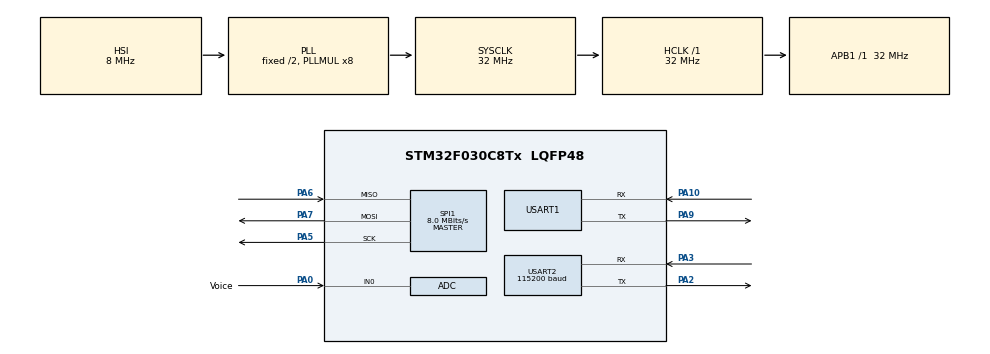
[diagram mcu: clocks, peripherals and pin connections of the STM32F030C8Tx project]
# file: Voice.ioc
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ADC.ClockPrescaler=ADC_CLOCK_ASYNC_DIV1
ADC.ContinuousConvMode=DISABLE
ADC.DMAContinuousRequests=ENABLE
ADC.DiscontinuousConvMode=DISABLE
ADC.ExternalTrigConv=ADC_SOFTWARE_START
ADC.Overrun=ADC_OVR_DATA_OVERWRITTEN
ADC.SamplingTime=ADC_SAMPLETIME_7CYCLES_5
Dma.ADC.1.Direction=DMA_PERIPH_TO_MEMORY
Dma.ADC.1.Instance=DMA1_Channel1
Dma.ADC.1.MemDataAlignment=DMA_MDATAALIGN_WORD
Dma.ADC.1.MemInc=DMA_MINC_ENABLE
Dma.ADC.1.Mode=DMA_CIRCULAR
Dma.ADC.1.PeriphDataAlignment=DMA_PDATAALIGN_WORD
Dma.ADC.1.PeriphInc=DMA_PINC_DISABLE
Dma.ADC.1.Priority=DMA_PRIORITY_LOW
Dma.Request0=SPI1_TX
Dma.Request1=ADC
Dma.SPI1_TX.0.Direction=DMA_MEMORY_TO_PERIPH
Dma.SPI1_TX.0.Instance=DMA1_Channel3
Dma.SPI1_TX.0.MemDataAlignment=DMA_MDATAALIGN_BYTE
Dma.SPI1_TX.0.MemInc=DMA_MINC_ENABLE
Dma.SPI1_TX.0.Mode=DMA_NORMAL
Dma.SPI1_TX.0.PeriphDataAlignment=DMA_PDATAALIGN_BYTE
Dma.SPI1_TX.0.PeriphInc=DMA_PINC_DISABLE
Dma.SPI1_TX.0.Priority=DMA_PRIORITY_LOW
Mcu.Family=STM32F0
Mcu.Name=STM32F030C8Tx
Mcu.Package=LQFP48
NVIC.DMA1_Channel1_IRQn=true\:0\:0\:false\:false\:true\:false\:true
NVIC.DMA1_Channel2_3_IRQn=true\:0\:0\:false\:false\:true\:false\:true
NVIC.TIM6_IRQn=true\:0\:0\:false\:false\:true\:false\:true
NVIC.TimeBase=TIM6_IRQn
NVIC.TimeBaseIP=TIM6
PA0.GPIO_Label=Voice
PA0.Mode=IN0
PA0.Signal=ADC_IN0
PA10.Mode=Asynchronous
PA10.Signal=USART1_RX
PA13.Mode=Serial_Wire
PA13.Signal=SYS_SWDIO
PA14.Mode=Serial_Wire
PA14.Signal=SYS_SWCLK
PA2.Mode=Asynchronous
PA2.Signal=USART2_TX
PA3.Mode=Asynchronous
PA3.Signal=USART2_RX
PA5.Mode=Full_Duplex_Master
PA5.Signal=SPI1_SCK
PA6.Mode=Full_Duplex_Master
PA6.Signal=SPI1_MISO
PA7.Mode=Full_Duplex_Master
PA7.Signal=SPI1_MOSI
PA9.Mode=Asynchronous
PA9.Signal=USART1_TX
PF0-OSC_IN.Mode=HSE-External-Oscillator
PF0-OSC_IN.Signal=RCC_OSC_IN
PF1-OSC_OUT.Mode=HSE-External-Oscillator
PF1-OSC_OUT.Signal=RCC_OSC_OUT
ProjectManager.HeapSize=0x200
ProjectManager.StackSize=0x400
ProjectManager.TargetToolchain=MDK-ARM V5
RCC.AHBFreq_Value=32000000
RCC.APB1Freq_Value=32000000
RCC.APB1TimFreq_Value=32000000
RCC.HCLKFreq_Value=32000000
RCC.PLLMUL=RCC_PLL_MUL8
RCC.SYSCLKFreq_VALUE=32000000
RCC.SYSCLKSource=RCC_SYSCLKSOURCE_PLLCLK
SPI1.BaudRatePrescaler=SPI_BAUDRATEPRESCALER_4
SPI1.CalculateBaudRate=8.0 MBits/s
SPI1.DataSize=SPI_DATASIZE_8BIT
SPI1.Direction=SPI_DIRECTION_2LINES
SPI1.Mode=SPI_MODE_MASTER
SPI1.VirtualType=VM_MASTER
USART1.VirtualMode-Asynchronous=VM_ASYNC
USART2.BaudRate=115200
USART2.VirtualMode-Asynchronous=VM_ASYNC
VP_SYS_VS_tim6.Mode=TIM6
board=custom

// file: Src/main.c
/* USER CODE BEGIN Header */
/**
  ******************************************************************************
  * @file           : main.c
  * @brief          : Main program body
  ******************************************************************************
  * @attention
  *
  * <h2><center>&copy; Copyright (c) 2019 STMicroelectronics.
  * All rights reserved.</center></h2>
  *
  * This software component is licensed by ST under BSD 3-Clause license,
  * the "License"; You may not use this file except in compliance with the
  * License. You may obtain a copy of the License at:
  *                        opensource.org/licenses/BSD-3-Clause
  *
  ******************************************************************************
  */
/* USER CODE END Header */

#include "main.h"
#include "adc.h"
#include "dma.h"
#include "spi.h"
#include "usart.h"
#include "gpio.h"

void SystemClock_Config(void);
/* USER CODE BEGIN PFP */
#define ADC_CONVERTED_DATA_BUFFER_SIZE   ((uint32_t)  30)   /* Size of array aADCxConvertedData[] */
static uint32_t   aADCxConvertedData[ADC_CONVERTED_DATA_BUFFER_SIZE];
/* USER CODE END PFP */

int main(void)
{

  /* MCU Configuration--------------------------------------------------------*/

  /* Reset of all peripherals, Initializes the Flash interface and the Systick. */
  HAL_Init();

  /* Configure the system clock */
  SystemClock_Config();

  /* Initialize all configured peripherals */
  MX_GPIO_Init();
  MX_DMA_Init();
  MX_ADC_Init();
  MX_SPI1_Init();
  MX_USART1_UART_Init();
  MX_USART2_UART_Init();
  /* USER CODE BEGIN 2 */

//	uint32_t AD_Voice[30];
//	HAL_ADCEx_Calibration_Start(&hadc);
//	HAL_ADC_Start_DMA(&hadc, (uint32_t *)AD_Voice,30);

	if (HAL_ADCEx_Calibration_Start(&hadc) != HAL_OK)
  {
		printf("HAL_ADCEx_Calibration_Start");
    Error_Handler();
  }
	if (HAL_ADC_Start_DMA(&hadc,
                        (uint32_t *)aADCxConvertedData,
                        ADC_CONVERTED_DATA_BUFFER_SIZE
                       ) != HAL_OK)
  {
		printf("HAL_ADC_Start_DMA");
    Error_Handler();
  }
	HAL_Delay(100);
  /* USER CODE END 2 */

  /* Infinite loop */
  /* USER CODE BEGIN WHILE */

  while (1)
  {
		printf("\r\n-------------------");
		for(int i = 0; i < ADC_CONVERTED_DATA_BUFFER_SIZE; i++)
		{
//				printf("\r\n---%d", aADCxConvertedData[i]);
//				HAL_Delay(1);
		}
//		HAL_ADC_Start(&hadc);
//		HAL_ADC_PollForConversion(&hadc, 50);
//
//      /* Check if the continous conversion of regular channel is finished */
//      if(HAL_IS_BIT_SET(HAL_ADC_GetState(&hadc), HAL_ADC_STATE_REG_EOC))
//      {
//          /*##-3- Get the converted value of regular channel  ######################*/
//          AD_Voice[0] = HAL_ADC_GetValue(&hadc);
//					printf("\r\n---%d", AD_Voice[0]);
//      }
//      HAL_Delay(10);
    /* USER CODE END WHILE */

  }
}

void SystemClock_Config(void)
{
  RCC_OscInitTypeDef RCC_OscInitStruct = {0};
  RCC_ClkInitTypeDef RCC_ClkInitStruct = {0};
  RCC_PeriphCLKInitTypeDef PeriphClkInit = {0};

  /** Initializes the CPU, AHB and APB busses clocks
  */
  RCC_OscInitStruct.OscillatorType = RCC_OSCILLATORTYPE_HSI|RCC_OSCILLATORTYPE_HSI14;
  RCC_OscInitStruct.HSIState = RCC_HSI_ON;
  RCC_OscInitStruct.HSI14State = RCC_HSI14_ON;
  RCC_OscInitStruct.HSICalibrationValue = RCC_HSICALIBRATION_DEFAULT;
  RCC_OscInitStruct.HSI14CalibrationValue = 16;
  RCC_OscInitStruct.PLL.PLLState = RCC_PLL_ON;
  RCC_OscInitStruct.PLL.PLLSource = RCC_PLLSOURCE_HSI;
  RCC_OscInitStruct.PLL.PLLMUL = RCC_PLL_MUL8;
  RCC_OscInitStruct.PLL.PREDIV = RCC_PREDIV_DIV1;
  if (HAL_RCC_OscConfig(&RCC_OscInitStruct) != HAL_OK)
  {
    Error_Handler();
  }
  /** Initializes the CPU, AHB and APB busses clocks
  */
  RCC_ClkInitStruct.ClockType = RCC_CLOCKTYPE_HCLK|RCC_CLOCKTYPE_SYSCLK
                              |RCC_CLOCKTYPE_PCLK1;
  RCC_ClkInitStruct.SYSCLKSource = RCC_SYSCLKSOURCE_PLLCLK;
  RCC_ClkInitStruct.AHBCLKDivider = RCC_SYSCLK_DIV1;
  RCC_ClkInitStruct.APB1CLKDivider = RCC_HCLK_DIV1;

  if (HAL_RCC_ClockConfig(&RCC_ClkInitStruct, FLASH_LATENCY_1) != HAL_OK)
  {
    Error_Handler();
  }
  PeriphClkInit.PeriphClockSelection = RCC_PERIPHCLK_USART1;
  PeriphClkInit.Usart1ClockSelection = RCC_USART1CLKSOURCE_PCLK1;
  if (HAL_RCCEx_PeriphCLKConfig(&PeriphClkInit) != HAL_OK)
  {
    Error_Handler();
  }
}

void HAL_TIM_PeriodElapsedCallback(TIM_HandleTypeDef *htim)
{
  if (htim->Instance == TIM6) {
    HAL_IncTick();
  }
}

void Error_Handler(void)
{
}

/************************ (C) COPYRIGHT STMicroelectronics *****END OF FILE****/
